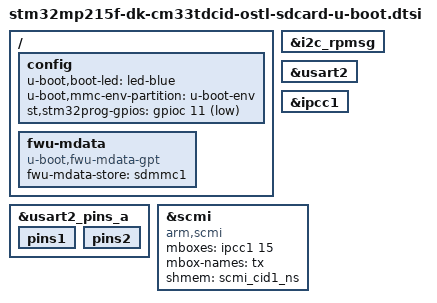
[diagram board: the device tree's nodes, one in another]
// SPDX-License-Identifier: (GPL-2.0-only OR BSD-3-Clause)
/*
 * Copyright (C) STMicroelectronics 2024 - All Rights Reserved
 */

#include "stm32mp21-u-boot.dtsi"

/ {
	config {
		u-boot,boot-led = "led-blue";
		u-boot,mmc-env-partition = "u-boot-env";
		st,stm32prog-gpios = <&gpioc 11 (GPIO_ACTIVE_LOW | GPIO_PULL_UP)>; // TOCHECK
	};

	fwu-mdata {
		compatible = "u-boot,fwu-mdata-gpt";
		fwu-mdata-store = <&sdmmc1>;
	};
};

&i2c_rpmsg {
	/delete-node/ typec@35;
};

&usart2 {
	bootph-all;
};

&usart2_pins_a {
	bootph-all;
	pins1 {
		bootph-all;
	};
	pins2 {
		bootph-all;
	};
};

&ipcc1 {
	bootph-all;
	/delete-property/ clocks;
	status = "okay";
};

&scmi {
	compatible = "arm,scmi";
	#address-cells = <1>;
	#size-cells = <0>;
	mboxes = <&ipcc1 15>;
	mbox-names = "tx";
	shmem = <&scmi_cid1_ns>;
	/delete-property/ linaro,optee-channel-id;
};

